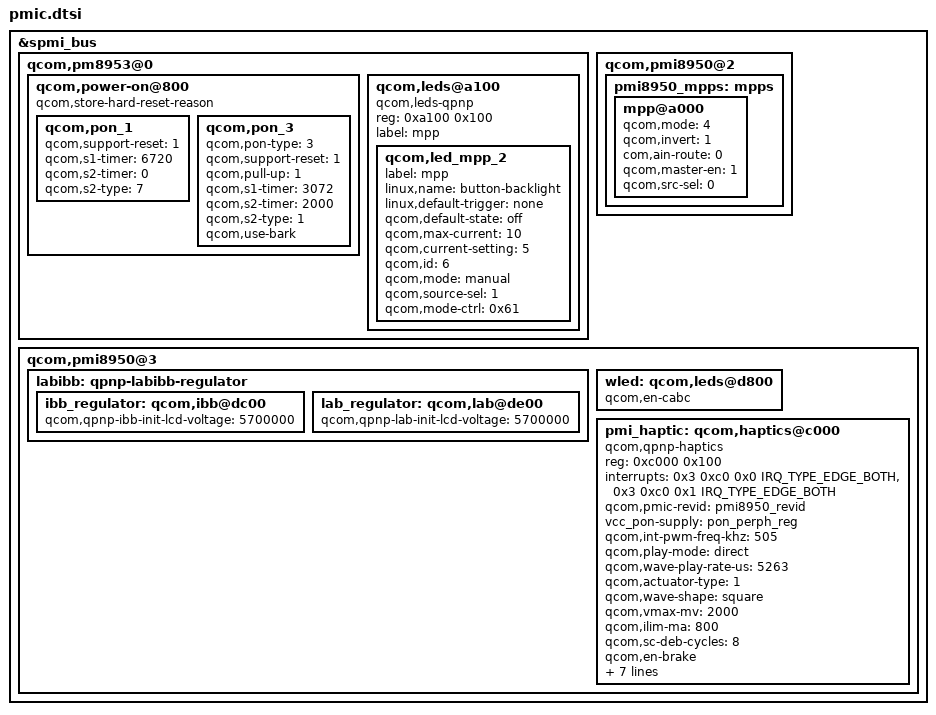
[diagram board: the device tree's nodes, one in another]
&spmi_bus {
	qcom,pm8953@0 {
		qcom,power-on@800 {
			qcom,store-hard-reset-reason;
			qcom,pon_1 {
				qcom,support-reset = <1>;
				qcom,s1-timer = <6720>;
				qcom,s2-timer = <0>;
				qcom,s2-type = <7>;
			};

			qcom,pon_3 {
				qcom,pon-type = <3>;
				qcom,support-reset = <1>;
				qcom,pull-up = <1>;
				qcom,s1-timer = <3072>;
				qcom,s2-timer = <2000>;
				qcom,s2-type = <1>;
				qcom,use-bark;
			};
		};
	};
};

&spmi_bus {
	qcom,pm8953@0 {
		qcom,leds@a100 {
			status = "okay";
			compatible = "qcom,leds-qpnp";
			reg = <0xa100 0x100>;
			label = "mpp";
			qcom,led_mpp_2 {
				label = "mpp";
				linux,name = "button-backlight";
				linux,default-trigger = "none";
				qcom,default-state = "off";
				qcom,max-current = <10>;
				qcom,current-setting = <5>;
				qcom,id = <6>;
				qcom,mode = "manual";
				qcom,source-sel = <1>;
				qcom,mode-ctrl = <0x61>;
			};
		};
	};
};

&spmi_bus {
	qcom,pmi8950@2 {
		pmi8950_mpps: mpps {
			mpp@a000 {
				qcom,mode = <4>; /* AIN input */
				qcom,invert = <1>; /* Enable MPP */
				com,ain-route = <0>; /* AMUX 5 */
				qcom,master-en = <1>;
				qcom,src-sel = <0>; /* Function constant */
				status = "okay";
			};
		};
	};

	qcom,pmi8950@3 {
        labibb: qpnp-labibb-regulator {
			status = "ok";
			ibb_regulator: qcom,ibb@dc00 {
				qcom,qpnp-ibb-init-lcd-voltage = <5700000>;
			};
			lab_regulator: qcom,lab@de00 {
				qcom,qpnp-lab-init-lcd-voltage = <5700000>;
			};
		};
		wled: qcom,leds@d800 {
			qcom,en-cabc;
		};

		pmi_haptic: qcom,haptics@c000 {
			compatible = "qcom,qpnp-haptics";
			reg = <0xc000 0x100>;
			interrupts = <0x3 0xc0 0x0 IRQ_TYPE_EDGE_BOTH>,
					<0x3 0xc0 0x1 IRQ_TYPE_EDGE_BOTH>;
			interrupt-names = "hap-sc-irq", "hap-play-irq";
			qcom,pmic-revid = <&pmi8950_revid>;
			vcc_pon-supply = <&pon_perph_reg>;
			qcom,int-pwm-freq-khz = <505>;
			qcom,play-mode = "direct";
			qcom,wave-play-rate-us = <5263>;
			qcom,actuator-type = <1>;
			qcom,wave-shape = "square";
			qcom,vmax-mv = <2000>;
			qcom,ilim-ma = <800>;
			qcom,sc-deb-cycles = <8>;
			qcom,en-brake;
			qcom,brake-pattern = <0x3 0x3 0x0 0x0>;
			qcom,wave-samples = <0x3e 0x3e 0x3e 0x3e 0x3e
							0x3e 0x3e 0x3e>;
			qcom,wave-rep-cnt = <1>;
			qcom,wave-samp-rep-cnt = <1>;
			qcom,use-play-irq;
			qcom,use-sc-irq;
			status = "okay";
		};
	};
};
